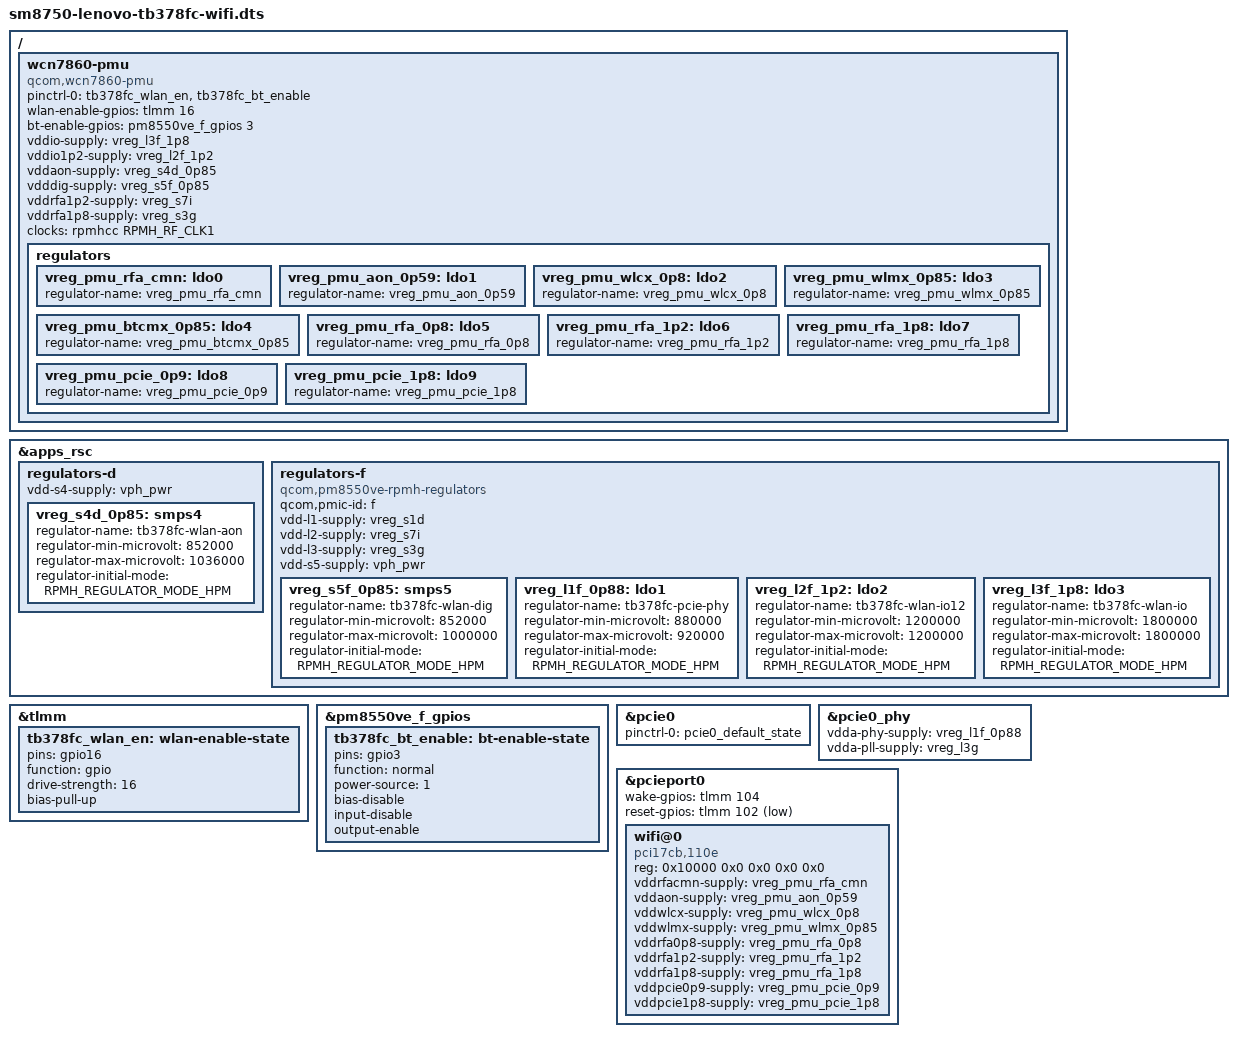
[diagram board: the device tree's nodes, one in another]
// SPDX-License-Identifier: BSD-3-Clause
/* TB378FC WCN7860 bring-up: native supply/gpio mapping checked by generator.
 * Firmware/board-data selection and Wi-Fi operation are not yet verified.
 */
#include "sm8750-lenovo-tb378fc-gpu.dts"

/ {
	wcn7860-pmu {
		compatible = "qcom,wcn7860-pmu";

		pinctrl-names = "default";
		pinctrl-0 = <&tb378fc_wlan_en>, <&tb378fc_bt_enable>;

		wlan-enable-gpios = <&tlmm 16 GPIO_ACTIVE_HIGH>;
		bt-enable-gpios = <&pm8550ve_f_gpios 3 GPIO_ACTIVE_HIGH>;

		vddio-supply = <&vreg_l3f_1p8>;
		vddio1p2-supply = <&vreg_l2f_1p2>;
		vddaon-supply = <&vreg_s4d_0p85>;
		vdddig-supply = <&vreg_s5f_0p85>;
		vddrfa1p2-supply = <&vreg_s7i>;
		vddrfa1p8-supply = <&vreg_s3g>;

		clocks = <&rpmhcc RPMH_RF_CLK1>;

		regulators {
			vreg_pmu_rfa_cmn: ldo0 {
				regulator-name = "vreg_pmu_rfa_cmn";
			};

			vreg_pmu_aon_0p59: ldo1 {
				regulator-name = "vreg_pmu_aon_0p59";
			};

			vreg_pmu_wlcx_0p8: ldo2 {
				regulator-name = "vreg_pmu_wlcx_0p8";
			};

			vreg_pmu_wlmx_0p85: ldo3 {
				regulator-name = "vreg_pmu_wlmx_0p85";
			};

			vreg_pmu_btcmx_0p85: ldo4 {
				regulator-name = "vreg_pmu_btcmx_0p85";
			};

			vreg_pmu_rfa_0p8: ldo5 {
				regulator-name = "vreg_pmu_rfa_0p8";
			};

			vreg_pmu_rfa_1p2: ldo6 {
				regulator-name = "vreg_pmu_rfa_1p2";
			};

			vreg_pmu_rfa_1p8: ldo7 {
				regulator-name = "vreg_pmu_rfa_1p8";
			};

			vreg_pmu_pcie_0p9: ldo8 {
				regulator-name = "vreg_pmu_pcie_0p9";
			};

			vreg_pmu_pcie_1p8: ldo9 {
				regulator-name = "vreg_pmu_pcie_1p8";
			};
		};
	};
};

&apps_rsc {
    regulators-d {
        vdd-s4-supply = <&vph_pwr>;
        vreg_s4d_0p85: smps4 {
            regulator-name = "tb378fc-wlan-aon";
            regulator-min-microvolt = <852000>;
            regulator-max-microvolt = <1036000>;
            regulator-initial-mode = <RPMH_REGULATOR_MODE_HPM>;
        };
    };
    regulators-f {
        compatible = "qcom,pm8550ve-rpmh-regulators";
        qcom,pmic-id = "f";
        vdd-l1-supply = <&vreg_s1d>;
        vdd-l2-supply = <&vreg_s7i>;
        vdd-l3-supply = <&vreg_s3g>;
        vdd-s5-supply = <&vph_pwr>;
        vreg_s5f_0p85: smps5 {
            regulator-name = "tb378fc-wlan-dig";
            regulator-min-microvolt = <852000>;
            regulator-max-microvolt = <1000000>;
            regulator-initial-mode = <RPMH_REGULATOR_MODE_HPM>;
        };
        vreg_l1f_0p88: ldo1 {
            regulator-name = "tb378fc-pcie-phy";
            regulator-min-microvolt = <880000>;
            regulator-max-microvolt = <920000>;
            regulator-initial-mode = <RPMH_REGULATOR_MODE_HPM>;
        };
        vreg_l2f_1p2: ldo2 {
            regulator-name = "tb378fc-wlan-io12";
            regulator-min-microvolt = <1200000>;
            regulator-max-microvolt = <1200000>;
            regulator-initial-mode = <RPMH_REGULATOR_MODE_HPM>;
        };
        vreg_l3f_1p8: ldo3 {
            regulator-name = "tb378fc-wlan-io";
            regulator-min-microvolt = <1800000>;
            regulator-max-microvolt = <1800000>;
            regulator-initial-mode = <RPMH_REGULATOR_MODE_HPM>;
        };
    };
};

&tlmm {
    tb378fc_wlan_en: wlan-enable-state {
        pins = "gpio16";
        function = "gpio";
        drive-strength = <16>;
        bias-pull-up;
    };
};

&pm8550ve_f_gpios {
    tb378fc_bt_enable: bt-enable-state {
        pins = "gpio3";
        function = "normal";
        power-source = <1>;
        bias-disable;
        input-disable;
        output-enable;
    };
};

&pcie0 {
	pinctrl-0 = <&pcie0_default_state>;
	pinctrl-names = "default";

	status = "okay";
};

&pcie0_phy {
	vdda-phy-supply = <&vreg_l1f_0p88>;
	vdda-pll-supply = <&vreg_l3g>;

	status = "okay";
};

&pcieport0 {
	wake-gpios = <&tlmm 104 GPIO_ACTIVE_HIGH>;
	reset-gpios = <&tlmm 102 GPIO_ACTIVE_LOW>;

	wifi@0 {
		compatible = "pci17cb,110e";
		reg = <0x10000 0x0 0x0 0x0 0x0>;

		vddrfacmn-supply = <&vreg_pmu_rfa_cmn>;
		vddaon-supply = <&vreg_pmu_aon_0p59>;
		vddwlcx-supply = <&vreg_pmu_wlcx_0p8>;
		vddwlmx-supply = <&vreg_pmu_wlmx_0p85>;
		vddrfa0p8-supply = <&vreg_pmu_rfa_0p8>;
		vddrfa1p2-supply = <&vreg_pmu_rfa_1p2>;
		vddrfa1p8-supply = <&vreg_pmu_rfa_1p8>;
		vddpcie0p9-supply = <&vreg_pmu_pcie_0p9>;
		vddpcie1p8-supply = <&vreg_pmu_pcie_1p8>;
	};
};
